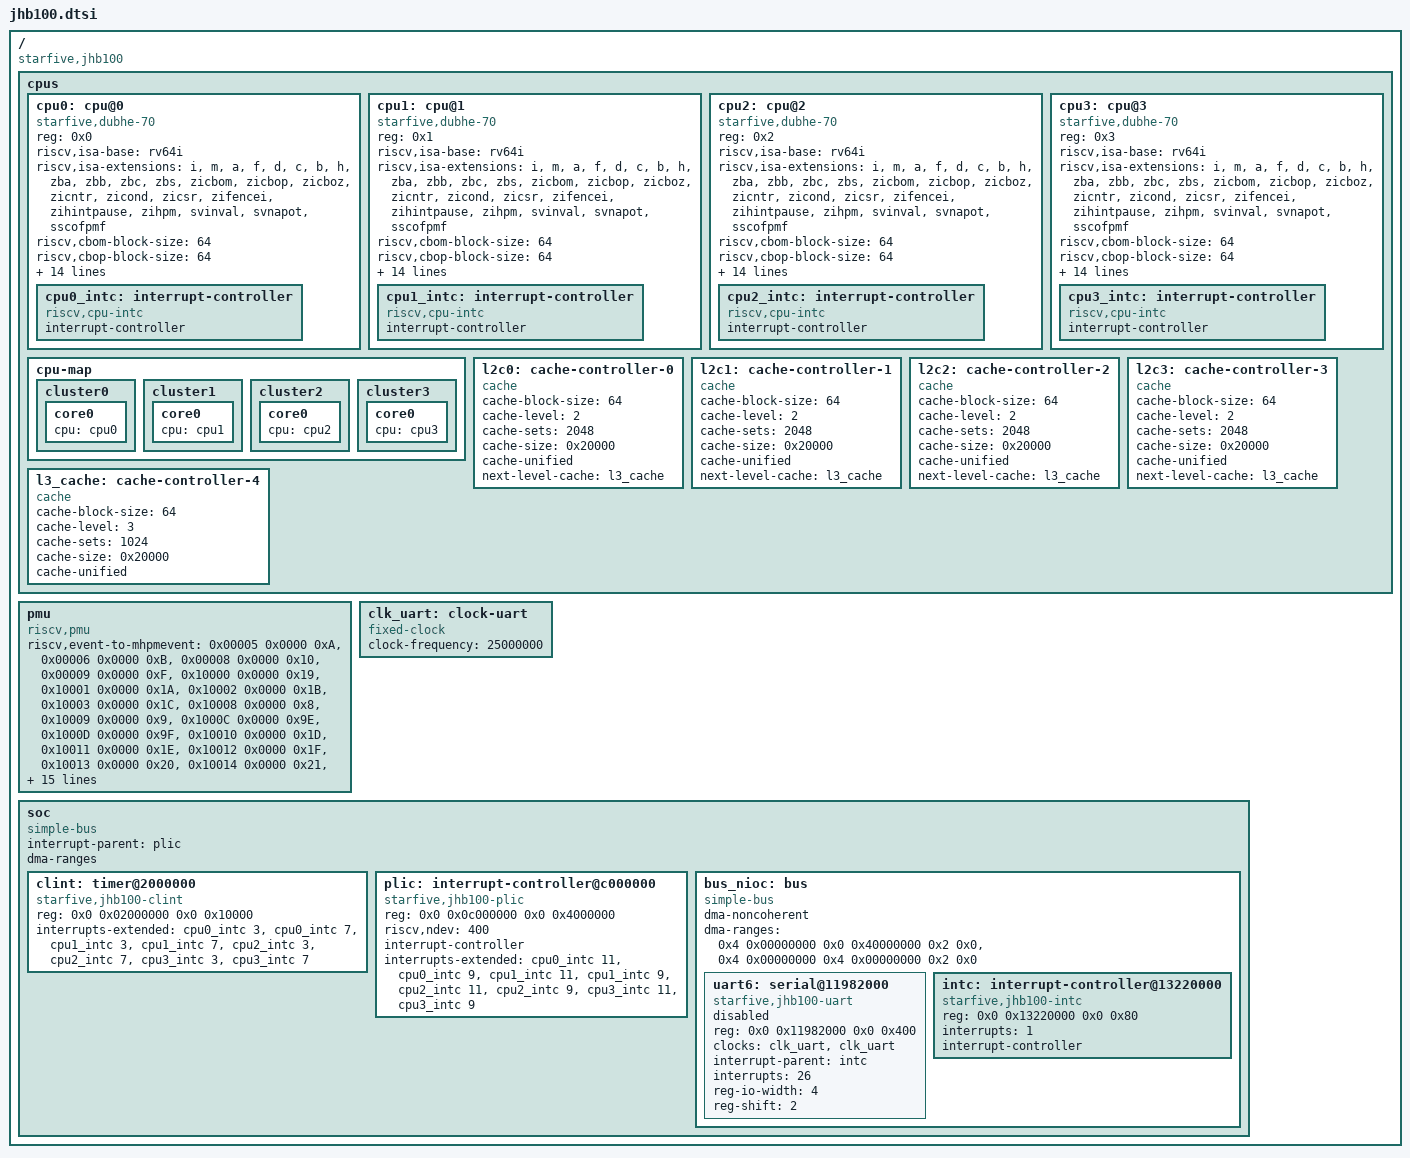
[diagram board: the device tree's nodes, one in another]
// SPDX-License-Identifier: GPL-2.0 OR MIT
/*
 * Copyright (c) 2024-2026 StarFive Technology Co., Ltd.
 */

/dts-v1/;

/ {
	compatible = "starfive,jhb100";
	#address-cells = <2>;
	#size-cells = <2>;

	cpus {
		#address-cells = <1>;
		#size-cells = <0>;

		cpu0: cpu@0 {
			compatible = "starfive,dubhe-70", "riscv";
			reg = <0x0>;
			riscv,isa-base = "rv64i";
			riscv,isa-extensions = "i", "m", "a", "f", "d", "c", "b", "h", "zba", "zbb",
					       "zbc", "zbs", "zicbom", "zicbop", "zicboz", "zicntr",
					       "zicond", "zicsr", "zifencei", "zihintpause",
					       "zihpm", "svinval", "svnapot", "sscofpmf";
			riscv,cbom-block-size = <64>;
			riscv,cbop-block-size = <64>;
			riscv,cboz-block-size = <64>;
			d-cache-block-size = <64>;
			d-cache-sets = <512>;
			d-cache-size = <32768>;
			d-tlb-sets = <1>;
			d-tlb-size = <16>;
			device_type = "cpu";
			i-cache-block-size = <64>;
			i-cache-sets = <512>;
			i-cache-size = <32768>;
			i-tlb-sets = <1>;
			i-tlb-size = <24>;
			mmu-type = "riscv,sv48";
			next-level-cache = <&l2c0>;
			tlb-split;

			cpu0_intc: interrupt-controller {
				compatible = "riscv,cpu-intc";
				interrupt-controller;
				#interrupt-cells = <1>;
			};
		};

		cpu1: cpu@1 {
			compatible = "starfive,dubhe-70", "riscv";
			reg = <0x1>;
			riscv,isa-base = "rv64i";
			riscv,isa-extensions = "i", "m", "a", "f", "d", "c", "b", "h", "zba", "zbb",
					       "zbc", "zbs", "zicbom", "zicbop", "zicboz", "zicntr",
					       "zicond", "zicsr", "zifencei", "zihintpause",
					       "zihpm", "svinval", "svnapot", "sscofpmf";
			riscv,cbom-block-size = <64>;
			riscv,cbop-block-size = <64>;
			riscv,cboz-block-size = <64>;
			d-cache-block-size = <64>;
			d-cache-sets = <512>;
			d-cache-size = <32768>;
			d-tlb-sets = <1>;
			d-tlb-size = <16>;
			device_type = "cpu";
			i-cache-block-size = <64>;
			i-cache-sets = <512>;
			i-cache-size = <32768>;
			i-tlb-sets = <1>;
			i-tlb-size = <24>;
			mmu-type = "riscv,sv48";
			next-level-cache = <&l2c1>;
			tlb-split;

			cpu1_intc: interrupt-controller {
				compatible = "riscv,cpu-intc";
				interrupt-controller;
				#interrupt-cells = <1>;
			};
		};

		cpu2: cpu@2 {
			compatible = "starfive,dubhe-70", "riscv";
			reg = <0x2>;
			riscv,isa-base = "rv64i";
			riscv,isa-extensions = "i", "m", "a", "f", "d", "c", "b", "h", "zba", "zbb",
					       "zbc", "zbs", "zicbom", "zicbop", "zicboz", "zicntr",
					       "zicond", "zicsr", "zifencei", "zihintpause",
					       "zihpm", "svinval", "svnapot", "sscofpmf";
			riscv,cbom-block-size = <64>;
			riscv,cbop-block-size = <64>;
			riscv,cboz-block-size = <64>;
			d-cache-block-size = <64>;
			d-cache-sets = <512>;
			d-cache-size = <32768>;
			d-tlb-sets = <1>;
			d-tlb-size = <16>;
			device_type = "cpu";
			i-cache-block-size = <64>;
			i-cache-sets = <512>;
			i-cache-size = <32768>;
			i-tlb-sets = <1>;
			i-tlb-size = <24>;
			mmu-type = "riscv,sv48";
			next-level-cache = <&l2c2>;
			tlb-split;

			cpu2_intc: interrupt-controller {
				compatible = "riscv,cpu-intc";
				interrupt-controller;
				#interrupt-cells = <1>;
			};
		};

		cpu3: cpu@3 {
			compatible = "starfive,dubhe-70", "riscv";
			reg = <0x3>;
			riscv,isa-base = "rv64i";
			riscv,isa-extensions = "i", "m", "a", "f", "d", "c", "b", "h", "zba", "zbb",
					       "zbc", "zbs", "zicbom", "zicbop", "zicboz", "zicntr",
					       "zicond", "zicsr", "zifencei", "zihintpause",
					       "zihpm", "svinval", "svnapot", "sscofpmf";
			riscv,cbom-block-size = <64>;
			riscv,cbop-block-size = <64>;
			riscv,cboz-block-size = <64>;
			d-cache-block-size = <64>;
			d-cache-sets = <512>;
			d-cache-size = <32768>;
			d-tlb-sets = <1>;
			d-tlb-size = <16>;
			device_type = "cpu";
			i-cache-block-size = <64>;
			i-cache-sets = <512>;
			i-cache-size = <32768>;
			i-tlb-sets = <1>;
			i-tlb-size = <24>;
			mmu-type = "riscv,sv48";
			next-level-cache = <&l2c3>;
			tlb-split;

			cpu3_intc: interrupt-controller {
				compatible = "riscv,cpu-intc";
				interrupt-controller;
				#interrupt-cells = <1>;
			};
		};

		cpu-map {
			cluster0 {
				core0 {
					cpu = <&cpu0>;
				};
			};

			cluster1 {
				core0 {
					cpu = <&cpu1>;
				};
			};

			cluster2 {
				core0 {
					cpu = <&cpu2>;
				};
			};

			cluster3 {
				core0 {
					cpu = <&cpu3>;
				};
			};
		};

		l2c0: cache-controller-0 {
			compatible = "cache";
			cache-block-size = <64>;
			cache-level = <2>;
			cache-sets = <2048>;
			cache-size = <0x20000>;
			cache-unified;
			next-level-cache = <&l3_cache>;
		};

		l2c1: cache-controller-1 {
			compatible = "cache";
			cache-block-size = <64>;
			cache-level = <2>;
			cache-sets = <2048>;
			cache-size = <0x20000>;
			cache-unified;
			next-level-cache = <&l3_cache>;
		};

		l2c2: cache-controller-2 {
			compatible = "cache";
			cache-block-size = <64>;
			cache-level = <2>;
			cache-sets = <2048>;
			cache-size = <0x20000>;
			cache-unified;
			next-level-cache = <&l3_cache>;
		};

		l2c3: cache-controller-3 {
			compatible = "cache";
			cache-block-size = <64>;
			cache-level = <2>;
			cache-sets = <2048>;
			cache-size = <0x20000>;
			cache-unified;
			next-level-cache = <&l3_cache>;
		};

		l3_cache: cache-controller-4 {
			compatible = "cache";
			cache-block-size = <64>;
			cache-level = <3>;
			cache-sets = <1024>;
			cache-size = <0x20000>;
			cache-unified;
		};
	};

	pmu {
		compatible = "riscv,pmu";

		riscv,event-to-mhpmevent = <0x00005 0x0000 0xA>,
					   <0x00006 0x0000 0xB>,
					   <0x00008 0x0000 0x10>,
					   <0x00009 0x0000 0xF>,
					   <0x10000 0x0000 0x19>,
					   <0x10001 0x0000 0x1A>,
					   <0x10002 0x0000 0x1B>,
					   <0x10003 0x0000 0x1C>,
					   <0x10008 0x0000 0x8>,
					   <0x10009 0x0000 0x9>,
					   <0x1000C 0x0000 0x9E>,
					   <0x1000D 0x0000 0x9F>,
					   <0x10010 0x0000 0x1D>,
					   <0x10011 0x0000 0x1E>,
					   <0x10012 0x0000 0x1F>,
					   <0x10013 0x0000 0x20>,
					   <0x10014 0x0000 0x21>,
					   <0x10018 0x0000 0x17>,
					   <0x10019 0x0000 0x18>,
					   <0x10020 0x0000 0x8>,
					   <0x10021 0x0000 0x7>;

		riscv,event-to-mhpmcounters = <0x00005 0x00006 0x00007FF8>,
					      <0x00008 0x00009 0x00007FF8>,
					      <0x10000 0x10003 0x00007FF8>,
					      <0x10008 0x10009 0x00007FF8>,
					      <0x1000C 0x1000D 0x00007FF8>,
					      <0x10010 0x10014 0x00007FF8>,
					      <0x10018 0x10019 0x00007FF8>,
					      <0x10020 0x10021 0x00007FF8>;

		riscv,raw-event-to-mhpmcounters =
			<0x00 0x00 0xFFFFFFFF 0xFFFFFFE0 0x00007FF8>,	/* Event ID 1-31 */
			<0x00 0x20 0xFFFFFFFF 0xFFFFFFFE 0x00007FF8>,	/* Event ID 32-33 */
			<0x00 0x22 0xFFFFFFFF 0xFFFFFF22 0x00007FF8>;	/* Event ID 34 */
	};

	clk_uart: clock-uart {
		compatible = "fixed-clock"; /* Initial clock handler for UART */
		#clock-cells = <0>;
		clock-frequency = <25000000>;
	};

	soc {
		compatible = "simple-bus";
		interrupt-parent = <&plic>;
		#address-cells = <2>;
		#size-cells = <2>;
		dma-ranges;
		ranges;

		clint: timer@2000000 {
			compatible = "starfive,jhb100-clint", "sifive,clint0";
			reg = <0x0 0x02000000 0x0 0x10000>;
			interrupts-extended = <&cpu0_intc 3>, <&cpu0_intc 7>,
					      <&cpu1_intc 3>, <&cpu1_intc 7>,
					      <&cpu2_intc 3>, <&cpu2_intc 7>,
					      <&cpu3_intc 3>, <&cpu3_intc 7>;
		};

		plic: interrupt-controller@c000000 {
			compatible = "starfive,jhb100-plic", "sifive,plic-1.0.0";
			reg = <0x0 0x0c000000 0x0 0x4000000>;
			riscv,ndev = <400>;
			interrupt-controller;
			#interrupt-cells = <1>;
			#address-cells = <0>;
			interrupts-extended = <&cpu0_intc 11>, <&cpu0_intc 9>,
					      <&cpu1_intc 11>, <&cpu1_intc 9>,
					      <&cpu2_intc 11>, <&cpu2_intc 9>,
					      <&cpu3_intc 11>, <&cpu3_intc 9>;
		};

		bus_nioc: bus {
			compatible = "simple-bus";
			#address-cells = <2>;
			#size-cells = <2>;
			dma-noncoherent;
			dma-ranges = <0x4 0x00000000 0x0 0x40000000 0x2 0x0>,
				     <0x4 0x00000000 0x4 0x00000000 0x2 0x0>;
			ranges;

			uart6: serial@11982000 {
				compatible = "starfive,jhb100-uart", "snps,dw-apb-uart";
				reg = <0x0 0x11982000 0x0 0x400>;
				clocks = <&clk_uart>, <&clk_uart>;
				clock-names = "baudclk", "apb_pclk";
				interrupt-parent = <&intc>;
				interrupts = <26>;
				reg-io-width = <4>;
				reg-shift = <2>;
				status = "disabled";
			};

			intc: interrupt-controller@13220000 {
				compatible = "starfive,jhb100-intc";
				reg = <0x0 0x13220000 0x0 0x80>;
				interrupts = <1>;
				interrupt-controller;
				#interrupt-cells = <1>;
			};
		};
	};
};
